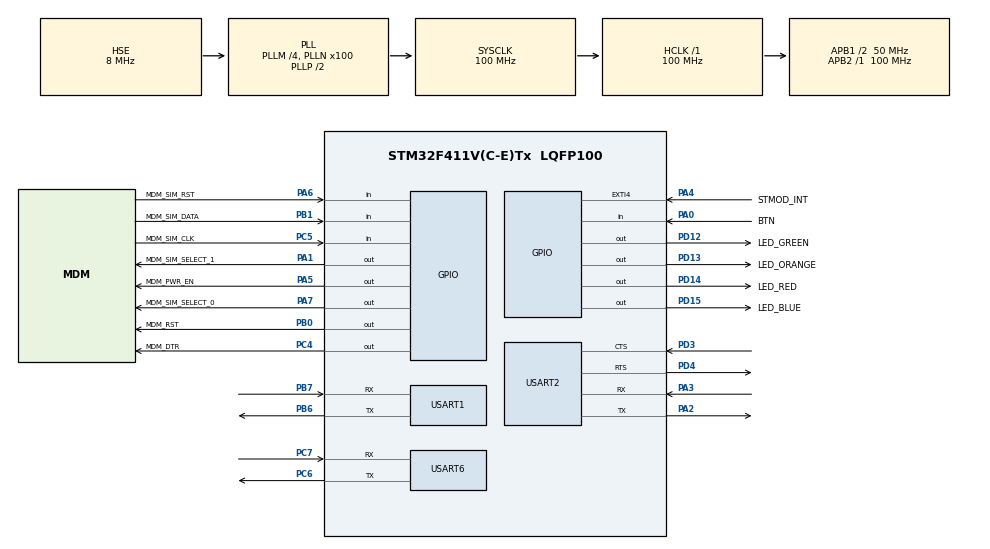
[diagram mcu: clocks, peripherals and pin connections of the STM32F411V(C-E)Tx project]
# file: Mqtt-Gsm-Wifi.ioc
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FREERTOS.Tasks01=defaultTask,24,128,StartDefaultTask,Default,NULL,Static,defaultTaskBuffer,defaultTaskControlBlock
FREERTOS.configCHECK_FOR_STACK_OVERFLOW=2
FREERTOS.configTOTAL_HEAP_SIZE=32768
Mcu.Family=STM32F4
Mcu.Name=STM32F411V(C-E)Tx
Mcu.Package=LQFP100
NVIC.PriorityGroup=NVIC_PRIORITYGROUP_4
NVIC.TIM1_UP_TIM10_IRQn=true\:0\:0\:false\:false\:true\:false\:false\:true
NVIC.TimeBase=TIM1_UP_TIM10_IRQn
NVIC.TimeBaseIP=TIM1
NVIC.USART1_IRQn=true\:7\:0\:true\:false\:true\:true\:true\:true
NVIC.USART2_IRQn=true\:7\:0\:true\:true\:true\:1\:false\:true\:true
NVIC.USART6_IRQn=true\:7\:0\:true\:false\:true\:true\:true\:true
PA0-WKUP.GPIO_Label=BTN
PA0-WKUP.Signal=GPIO_Input
PA1.GPIO_Label=MDM_SIM_SELECT_1
PA1.GPIO_PuPd=GPIO_PULLDOWN
PA1.Signal=GPIO_Output
PA13.Mode=Serial_Wire
PA13.Signal=SYS_JTMS-SWDIO
PA14.Mode=Serial_Wire
PA14.Signal=SYS_JTCK-SWCLK
PA2.Mode=Asynchronous
PA2.Signal=USART2_TX
PA3.Mode=Asynchronous
PA3.Signal=USART2_RX
PA4.GPIO_Label=STMOD_INT
PA4.Signal=GPXTI4
PA5.GPIO_Label=MDM_PWR_EN
PA5.PinState=GPIO_PIN_SET
PA5.Signal=GPIO_Output
PA6.GPIO_Label=MDM_SIM_RST
PA6.Signal=GPIO_Input
PA7.GPIO_Label=MDM_SIM_SELECT_0
PA7.GPIO_ModeDefaultOutputPP=GPIO_MODE_OUTPUT_PP
PA7.GPIO_PuPd=GPIO_PULLDOWN
PA7.Signal=GPIO_Output
PB0.GPIO_Label=MDM_RST
PB0.PinState=GPIO_PIN_SET
PB0.Signal=GPIO_Output
PB1.GPIO_Label=MDM_SIM_DATA
PB1.Signal=GPIO_Input
PB6.Mode=Asynchronous
PB6.Signal=USART1_TX
PB7.Mode=Asynchronous
PB7.Signal=USART1_RX
PC4.GPIO_Label=MDM_DTR
PC4.Signal=GPIO_Output
PC5.GPIO_Label=MDM_SIM_CLK
PC5.Signal=GPIO_Input
PC6.Mode=Asynchronous
PC6.Signal=USART6_TX
PC7.Mode=Asynchronous
PC7.Signal=USART6_RX
PD12.GPIO_Label=LED_GREEN
PD12.Signal=GPIO_Output
PD13.GPIO_Label=LED_ORANGE
PD13.Signal=GPIO_Output
PD14.GPIO_Label=LED_RED
PD14.Signal=GPIO_Output
PD15.GPIO_Label=LED_BLUE
PD15.Signal=GPIO_Output
PD3.Mode=CTS_RTS
PD3.Signal=USART2_CTS
PD4.Mode=CTS_RTS
PD4.Signal=USART2_RTS
PH0\ -\ OSC_IN.Mode=HSE-External-Oscillator
PH0\ -\ OSC_IN.Signal=RCC_OSC_IN
PH1\ -\ OSC_OUT.Mode=HSE-External-Oscillator
PH1\ -\ OSC_OUT.Signal=RCC_OSC_OUT
ProjectManager.HeapSize=0x2000
ProjectManager.StackSize=0x400
ProjectManager.TargetToolchain=STM32CubeIDE
RCC.48MHZClocksFreq_Value=50000000
RCC.AHBFreq_Value=100000000
RCC.APB1CLKDivider=RCC_HCLK_DIV2
RCC.APB1Freq_Value=50000000
RCC.APB1TimFreq_Value=100000000
RCC.APB2Freq_Value=100000000
RCC.APB2TimFreq_Value=100000000
RCC.CortexFreq_Value=100000000
RCC.HCLKFreq_Value=100000000
RCC.HSE_VALUE=8000000
RCC.HSI_VALUE=16000000
RCC.LSE_VALUE=32768
RCC.PLLM=4
RCC.PLLN=100
RCC.PLLSourceVirtual=RCC_PLLSOURCE_HSE
RCC.SYSCLKFreq_VALUE=100000000
RCC.SYSCLKSource=RCC_SYSCLKSOURCE_PLLCLK
RCC.VCOOutputFreq_Value=200000000
USART1.VirtualMode=VM_ASYNC
USART2.VirtualMode=VM_ASYNC
USART6.VirtualMode=VM_ASYNC
VP_FREERTOS_VS_CMSIS_V2.Mode=CMSIS_V2
VP_SYS_VS_tim1.Mode=TIM1
board=custom

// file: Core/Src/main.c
/* USER CODE BEGIN Header */
/**
  ******************************************************************************
  * @file           : main.c
  * @brief          : Main program body
  ******************************************************************************
  * @attention
  *
  * <h2><center>&copy; Copyright (c) 2019 STMicroelectronics.
  * All rights reserved.</center></h2>
  *
  * This software component is licensed by ST under BSD 3-Clause license,
  * the "License"; You may not use this file except in compliance with the
  * License. You may obtain a copy of the License at:
  *                        opensource.org/licenses/BSD-3-Clause
  *

  https://www.keil.com/pack/doc/cmsis/RTOS2/html/group__CMSIS__RTOS__SemaphoreMgmt.html#details

  Los semáforos se utilizan para administrar y proteger el acceso a los recursos
  compartidos. Los semáforos son muy similares a los mutexes. Mientras que un
  Mutex permite que solo un subproceso acceda a un recurso compartido a la vez,
  se puede utilizar un semáforo para permitir que un número fijo de subprocesos
  / ISR acceda a un grupo de recursos compartidos. Usando semáforos, se puede
  administrar el acceso a un grupo de periféricos idénticos
  (por ejemplo, múltiples canales DMA).
  ******************************************************************************
  */
/* USER CODE END Header */

#include "main.h"
#include "cmsis_os.h"

/* USER CODE BEGIN Includes */
#include "stdio.h"
#include <string.h>
#include "mytasks.h"
/* USER CODE END Includes */

UART_HandleTypeDef huart1;
UART_HandleTypeDef huart2;
UART_HandleTypeDef huart6;

typedef StaticTask_t osStaticThreadDef_t;
osThreadId_t defaultTaskHandle;
uint32_t defaultTaskBuffer[ 128 ];
osStaticThreadDef_t defaultTaskControlBlock;

void SystemClock_Config(void);
static void MX_GPIO_Init(void);
static void MX_USART2_UART_Init(void);
static void MX_USART1_UART_Init(void);
static void MX_USART6_UART_Init(void);
void StartDefaultTask(void *argument);

static void MX_NVIC_Init(void);
/* USER CODE BEGIN PFP */
/* Definitions for defaultTask */

/* USER CODE END PFP */

/* USER CODE BEGIN 0 */

int _write(int file, char *ptr, int len) {
	int i = 0;
	for (i = 0; i < len; i++)
		ITM_SendChar((*ptr++));
	return len;
}

/* USER CODE END 0 */

int main(void)
{

  /* MCU Configuration--------------------------------------------------------*/

  /* Reset of all peripherals, Initializes the Flash interface and the Systick. */
  HAL_Init();

  /* Configure the system clock */
  SystemClock_Config();

  /* USER CODE BEGIN SysInit */
  HAL_NVIC_SetPriorityGrouping(NVIC_PRIORITYGROUP_4);
  /* USER CODE END SysInit */

  /* Initialize all configured peripherals */
  MX_GPIO_Init();
  MX_USART2_UART_Init();
  MX_USART1_UART_Init();
  MX_USART6_UART_Init();

  /* Initialize interrupts */
  MX_NVIC_Init();

  osKernelInitialize();

  /* USER CODE BEGIN RTOS_MUTEX */
  /* add mutexes, ... */
  //The Mutex Management function group is used to synchronize the execution of threads.
  //This is for example used to protect access to a shared resource, for example a shared memory image.

  /* USER CODE END RTOS_MUTEX */

  /* USER CODE BEGIN RTOS_SEMAPHORES */
  /* add semaphores, ... */

  //Init_Semaphore();

  /* USER CODE END RTOS_SEMAPHORES */

  /* Create the thread(s) */
  /* definition and creation of defaultTask */
  const osThreadAttr_t defaultTask_attributes = {
    .name = "defaultTask",
    .stack_mem = &defaultTaskBuffer[0],
    .stack_size = sizeof(defaultTaskBuffer),
    .cb_mem = &defaultTaskControlBlock,
    .cb_size = sizeof(defaultTaskControlBlock),
    .priority = (osPriority_t) osPriorityNormal,
  };
  defaultTaskHandle = osThreadNew(StartDefaultTask, NULL, &defaultTask_attributes);

  /* USER CODE BEGIN RTOS_THREADS */

  //char txData[50]= "Inicio";
  //HAL_UART_Transmit(&huart2, (uint8_t *) txData, strlen(txData), 1000);

    printf("Iniciando\r\n");//simepre tiene que estar un primer printf para que funcione bien
    printf("Espere...\r\n");
    //uint8_t data[]="hola";
    //HAL_UART_Transmit_IT(&huart1, data, 4);

    initTasks();
  /* add threads, ... */
  /* USER CODE END RTOS_THREADS */

  /* Start scheduler */
  osKernelStart();

  /* We should never get here as control is now taken by the scheduler */

  /* Infinite loop */
  while (1)
  {

  }
}

void SystemClock_Config(void)
{
  RCC_OscInitTypeDef RCC_OscInitStruct = {0};
  RCC_ClkInitTypeDef RCC_ClkInitStruct = {0};

  /** Configure the main internal regulator output voltage
  */
  __HAL_RCC_PWR_CLK_ENABLE();
  __HAL_PWR_VOLTAGESCALING_CONFIG(PWR_REGULATOR_VOLTAGE_SCALE1);
  /** Initializes the CPU, AHB and APB busses clocks
  */
  RCC_OscInitStruct.OscillatorType = RCC_OSCILLATORTYPE_HSE;
  RCC_OscInitStruct.HSEState = RCC_HSE_ON;
  RCC_OscInitStruct.PLL.PLLState = RCC_PLL_ON;
  RCC_OscInitStruct.PLL.PLLSource = RCC_PLLSOURCE_HSE;
  RCC_OscInitStruct.PLL.PLLM = 4;
  RCC_OscInitStruct.PLL.PLLN = 100;
  RCC_OscInitStruct.PLL.PLLP = RCC_PLLP_DIV2;
  RCC_OscInitStruct.PLL.PLLQ = 4;
  if (HAL_RCC_OscConfig(&RCC_OscInitStruct) != HAL_OK)
  {
    Error_Handler();
  }
  /** Initializes the CPU, AHB and APB busses clocks
  */
  RCC_ClkInitStruct.ClockType = RCC_CLOCKTYPE_HCLK|RCC_CLOCKTYPE_SYSCLK
                              |RCC_CLOCKTYPE_PCLK1|RCC_CLOCKTYPE_PCLK2;
  RCC_ClkInitStruct.SYSCLKSource = RCC_SYSCLKSOURCE_PLLCLK;
  RCC_ClkInitStruct.AHBCLKDivider = RCC_SYSCLK_DIV1;
  RCC_ClkInitStruct.APB1CLKDivider = RCC_HCLK_DIV2;
  RCC_ClkInitStruct.APB2CLKDivider = RCC_HCLK_DIV1;

  if (HAL_RCC_ClockConfig(&RCC_ClkInitStruct, FLASH_LATENCY_3) != HAL_OK)
  {
    Error_Handler();
  }
}

/**
  * @brief NVIC Configuration.
  * @retval None
  */
static void MX_NVIC_Init(void)
{
  /* USART2_IRQn interrupt configuration */
  HAL_NVIC_SetPriority(USART2_IRQn, 7, 0);
  HAL_NVIC_EnableIRQ(USART2_IRQn);
}

static void MX_USART1_UART_Init(void)
{

  huart1.Instance = USART1;
  huart1.Init.BaudRate = 115200;
  huart1.Init.WordLength = UART_WORDLENGTH_8B;
  huart1.Init.StopBits = UART_STOPBITS_1;
  huart1.Init.Parity = UART_PARITY_NONE;
  huart1.Init.Mode = UART_MODE_TX_RX;
  huart1.Init.HwFlowCtl = UART_HWCONTROL_NONE;
  huart1.Init.OverSampling = UART_OVERSAMPLING_16;
  if (HAL_UART_Init(&huart1) != HAL_OK)
  {
    Error_Handler();
  }

}

static void MX_USART2_UART_Init(void)
{

  huart2.Instance = USART2;
  huart2.Init.BaudRate = 115200;
  huart2.Init.WordLength = UART_WORDLENGTH_8B;
  huart2.Init.StopBits = UART_STOPBITS_1;
  huart2.Init.Parity = UART_PARITY_NONE;
  huart2.Init.Mode = UART_MODE_TX_RX;
  huart2.Init.HwFlowCtl = UART_HWCONTROL_RTS_CTS;
  huart2.Init.OverSampling = UART_OVERSAMPLING_16;
  if (HAL_UART_Init(&huart2) != HAL_OK)
  {
    Error_Handler();
  }

}

static void MX_USART6_UART_Init(void)
{

  huart6.Instance = USART6;
  huart6.Init.BaudRate = 115200;
  huart6.Init.WordLength = UART_WORDLENGTH_8B;
  huart6.Init.StopBits = UART_STOPBITS_1;
  huart6.Init.Parity = UART_PARITY_NONE;
  huart6.Init.Mode = UART_MODE_TX_RX;
  huart6.Init.HwFlowCtl = UART_HWCONTROL_NONE;
  huart6.Init.OverSampling = UART_OVERSAMPLING_16;
  if (HAL_UART_Init(&huart6) != HAL_OK)
  {
    Error_Handler();
  }

}

static void MX_GPIO_Init(void)
{
  GPIO_InitTypeDef GPIO_InitStruct = {0};

  /* GPIO Ports Clock Enable */
  __HAL_RCC_GPIOH_CLK_ENABLE();
  __HAL_RCC_GPIOA_CLK_ENABLE();
  __HAL_RCC_GPIOC_CLK_ENABLE();
  __HAL_RCC_GPIOB_CLK_ENABLE();
  __HAL_RCC_GPIOD_CLK_ENABLE();

  /*Configure GPIO pin Output Level */
  HAL_GPIO_WritePin(GPIOA, MDM_SIM_SELECT_1_Pin|MDM_SIM_SELECT_0_Pin, GPIO_PIN_RESET);

  /*Configure GPIO pin Output Level */
  HAL_GPIO_WritePin(MDM_PWR_EN_GPIO_Port, MDM_PWR_EN_Pin, GPIO_PIN_SET);

  /*Configure GPIO pin Output Level */
  HAL_GPIO_WritePin(MDM_DTR_GPIO_Port, MDM_DTR_Pin, GPIO_PIN_RESET);

  /*Configure GPIO pin Output Level */
  HAL_GPIO_WritePin(MDM_RST_GPIO_Port, MDM_RST_Pin, GPIO_PIN_SET);

  /*Configure GPIO pin Output Level */
  HAL_GPIO_WritePin(GPIOD, LED_GREEN_Pin|LED_ORANGE_Pin|LED_RED_Pin|LED_BLUE_Pin, GPIO_PIN_RESET);

  /*Configure GPIO pins : BTN_Pin MDM_SIM_RST_Pin */
  GPIO_InitStruct.Pin = BTN_Pin|MDM_SIM_RST_Pin;
  GPIO_InitStruct.Mode = GPIO_MODE_INPUT;
  GPIO_InitStruct.Pull = GPIO_NOPULL;
  HAL_GPIO_Init(GPIOA, &GPIO_InitStruct);

  /*Configure GPIO pins : MDM_SIM_SELECT_1_Pin MDM_SIM_SELECT_0_Pin */
  GPIO_InitStruct.Pin = MDM_SIM_SELECT_1_Pin|MDM_SIM_SELECT_0_Pin;
  GPIO_InitStruct.Mode = GPIO_MODE_OUTPUT_PP;
  GPIO_InitStruct.Pull = GPIO_PULLDOWN;
  GPIO_InitStruct.Speed = GPIO_SPEED_FREQ_LOW;
  HAL_GPIO_Init(GPIOA, &GPIO_InitStruct);

  /*Configure GPIO pin : STMOD_INT_Pin */
  GPIO_InitStruct.Pin = STMOD_INT_Pin;
  GPIO_InitStruct.Mode = GPIO_MODE_IT_RISING;
  GPIO_InitStruct.Pull = GPIO_NOPULL;
  HAL_GPIO_Init(STMOD_INT_GPIO_Port, &GPIO_InitStruct);

  /*Configure GPIO pin : MDM_PWR_EN_Pin */
  GPIO_InitStruct.Pin = MDM_PWR_EN_Pin;
  GPIO_InitStruct.Mode = GPIO_MODE_OUTPUT_PP;
  GPIO_InitStruct.Pull = GPIO_NOPULL;
  GPIO_InitStruct.Speed = GPIO_SPEED_FREQ_LOW;
  HAL_GPIO_Init(MDM_PWR_EN_GPIO_Port, &GPIO_InitStruct);

  /*Configure GPIO pin : MDM_DTR_Pin */
  GPIO_InitStruct.Pin = MDM_DTR_Pin;
  GPIO_InitStruct.Mode = GPIO_MODE_OUTPUT_PP;
  GPIO_InitStruct.Pull = GPIO_NOPULL;
  GPIO_InitStruct.Speed = GPIO_SPEED_FREQ_LOW;
  HAL_GPIO_Init(MDM_DTR_GPIO_Port, &GPIO_InitStruct);

  /*Configure GPIO pin : MDM_SIM_CLK_Pin */
  GPIO_InitStruct.Pin = MDM_SIM_CLK_Pin;
  GPIO_InitStruct.Mode = GPIO_MODE_INPUT;
  GPIO_InitStruct.Pull = GPIO_NOPULL;
  HAL_GPIO_Init(MDM_SIM_CLK_GPIO_Port, &GPIO_InitStruct);

  /*Configure GPIO pin : MDM_RST_Pin */
  GPIO_InitStruct.Pin = MDM_RST_Pin;
  GPIO_InitStruct.Mode = GPIO_MODE_OUTPUT_PP;
  GPIO_InitStruct.Pull = GPIO_NOPULL;
  GPIO_InitStruct.Speed = GPIO_SPEED_FREQ_LOW;
  HAL_GPIO_Init(MDM_RST_GPIO_Port, &GPIO_InitStruct);

  /*Configure GPIO pin : MDM_SIM_DATA_Pin */
  GPIO_InitStruct.Pin = MDM_SIM_DATA_Pin;
  GPIO_InitStruct.Mode = GPIO_MODE_INPUT;
  GPIO_InitStruct.Pull = GPIO_NOPULL;
  HAL_GPIO_Init(MDM_SIM_DATA_GPIO_Port, &GPIO_InitStruct);

  /*Configure GPIO pins : LED_GREEN_Pin LED_ORANGE_Pin LED_RED_Pin LED_BLUE_Pin */
  GPIO_InitStruct.Pin = LED_GREEN_Pin|LED_ORANGE_Pin|LED_RED_Pin|LED_BLUE_Pin;
  GPIO_InitStruct.Mode = GPIO_MODE_OUTPUT_PP;
  GPIO_InitStruct.Pull = GPIO_NOPULL;
  GPIO_InitStruct.Speed = GPIO_SPEED_FREQ_LOW;
  HAL_GPIO_Init(GPIOD, &GPIO_InitStruct);

}

void StartDefaultTask(void *argument)
{
  /* USER CODE BEGIN 5 */
  /* Infinite loop */
  for(;;)
  {
	  //HAL_GPIO_TogglePin(LED_BLUE_GPIO_Port, LED_BLUE_Pin);

	  osDelay(100);
  }
  /* USER CODE END 5 */
}

void HAL_TIM_PeriodElapsedCallback(TIM_HandleTypeDef *htim)
{
  if (htim->Instance == TIM1) {
    HAL_IncTick();
  }
}

void Error_Handler(void)
{
}

/************************ (C) COPYRIGHT STMicroelectronics *****END OF FILE****/

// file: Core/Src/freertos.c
/* USER CODE BEGIN Header */
/**
  ******************************************************************************
  * File Name          : freertos.c
  * Description        : Code for freertos applications
  ******************************************************************************
  * @attention
  *
  * <h2><center>&copy; Copyright (c) 2019 STMicroelectronics.
  * All rights reserved.</center></h2>
  *
  * This software component is licensed by ST under Ultimate Liberty license
  * SLA0044, the "License"; You may not use this file except in compliance with
  * the License. You may obtain a copy of the License at:
  *                             www.st.com/SLA0044
  *
  ******************************************************************************
  */
/* USER CODE END Header */

#include "FreeRTOS.h"
#include "task.h"
#include "main.h"

/* Hook prototypes */
void vApplicationStackOverflowHook(xTaskHandle xTask, signed char *pcTaskName);

/* USER CODE BEGIN 4 */
__weak void vApplicationStackOverflowHook(xTaskHandle xTask, signed char *pcTaskName)
{
   /* Run time stack overflow checking is performed if
   configCHECK_FOR_STACK_OVERFLOW is defined to 1 or 2. This hook function is
   called if a stack overflow is detected. */
	while(1)
	{

	}
}
/* USER CODE END 4 */

/************************ (C) COPYRIGHT STMicroelectronics *****END OF FILE****/
